# STM32H7P4 register map
File version: 2.0.0
CPU: CM7 r1p2, little endian, MPU, FPU, 4 interrupt priority bits
Registers are 32-bit, read-write, reset 0x0 unless marked. A register's access mark holds for its fields unless they carry their own. Offsets are from the block's base; [hi:lo] are bit positions; {n}, {i} and the like mark numbered series; 'fields as' and 'values as' point back to an identical list.

## EXTI — EXTI register block
Base 0x58000000
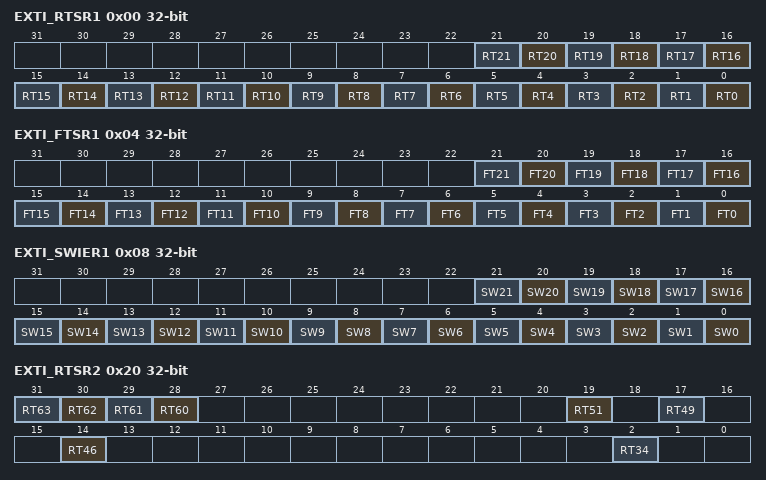
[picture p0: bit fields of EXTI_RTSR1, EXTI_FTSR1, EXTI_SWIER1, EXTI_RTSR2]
0x00 EXTI_RTSR1 — EXTI rising trigger selection register 1
  [all] fields
    0=Rising trigger disabled (for event and interrupt) for input line i; 1=Rising trigger enabled (for event and interrupt) for input line i
  [n] RT{n} (n=0..21) — Rising trigger event configuration bit of configurable event input i
0x04 EXTI_FTSR1 — EXTI falling trigger selection register 1
  [all] fields
    0=Falling trigger disabled (for event and interrupt) for input line i; 1=Falling trigger enabled (for event and interrupt) for input line i
  [n] FT{n} (n=0..21) — Falling trigger event configuration bit of configurable event input i
0x08 EXTI_SWIER1 — EXTI software interrupt event register 1
  [all] fields
    0=Writing 0 has no effect; 1=Writing a 1 to this bit triggers an event on line i. This bit is auto cleared by hardware.
  [n] SW{n} (n=0..21) — Software interrupt on event i
0x20 EXTI_RTSR2 — EXTI rising trigger selection register 2
  [n-32] RT{n} (n=60..63) — Rising trigger event configuration bit of configurable event input i
    values as the fields of EXTI_RTSR1
  [19] RT51 — Rising trigger event configuration bit of configurable event input 51less thansup>(1)less than/sup>
    0=Rising trigger disabled (for event and interrupt) for input line 51; 1=Rising trigger enabled (for event and interrupt) for input line 51
  [17] RT49 — Rising trigger event configuration bit of configurable event input 49less thansup>(1)less than/sup>
    0=Rising trigger disabled (for event and interrupt) for input line 49; 1=Rising trigger enabled (for event and interrupt) for input line 49
  [14] RT46 — Rising trigger event configuration bit of configurable event input 46less thansup>(1)less than/sup>
    0=Rising trigger disabled (for event and interrupt) for input line 46; 1=Rising trigger enabled (for event and interrupt) for input line 46
  [2] RT34 — Rising trigger event configuration bit of configurable event input 34less thansup>(1)less than/sup>
    0=Rising trigger disabled (for event and interrupt) for input line 34; 1=Rising trigger enabled (for event and interrupt) for input line 34
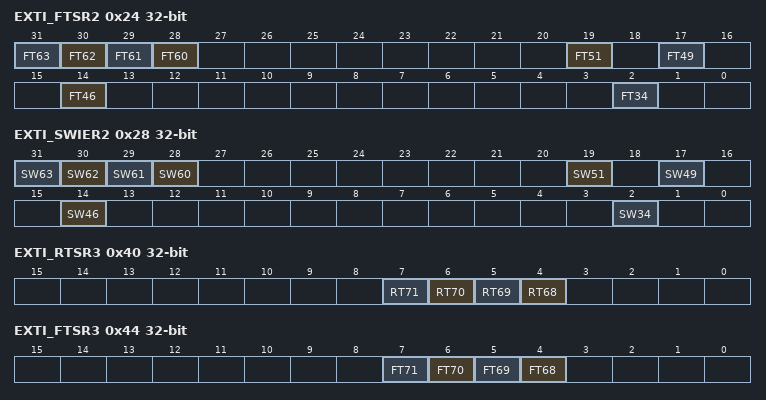
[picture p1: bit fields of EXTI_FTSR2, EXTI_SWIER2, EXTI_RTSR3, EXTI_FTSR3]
0x24 EXTI_FTSR2 — EXTI falling trigger selection register 2
  [n-32] FT{n} (n=60..63) — Falling trigger event configuration bit of configurable event input i
    values as the fields of EXTI_FTSR1
  [19] FT51 — Falling trigger event configuration bit of configurable event input 51less thansup>(1)less than/sup>
    0=Falling trigger disabled (for event and interrupt) for input line 51; 1=Falling trigger enabled (for event and interrupt) for input line 51
  [17] FT49 — Falling trigger event configuration bit of configurable event input 49less thansup>(1)less than/sup>
    0=Falling trigger disabled (for event and interrupt) for input line 49; 1=Falling trigger enabled (for event and interrupt) for input line 49
  [14] FT46 — Falling trigger event configuration bit of configurable event input 46less thansup>(1)less than/sup>
    0=Falling trigger disabled (for event and interrupt) for input line 46; 1=Falling trigger enabled (for event and interrupt) for input line 46
  [2] FT34 — Falling trigger event configuration bit of configurable event input 34less thansup>(1)less than/sup>
    0=Falling trigger disabled (for event and interrupt) for input line 34; 1=Falling trigger enabled (for event and interrupt) for input line 34
0x28 EXTI_SWIER2 — EXTI software interrupt event register 2
  [n-32] SW{n} (n=60..63) — Software interrupt on event i
    values as the fields of EXTI_SWIER1
  [19] SW51 — Software interrupt on event 51
    0=Writing 0 has no effect; 1=Writing a 1 to this bit triggers an event on line 51. This bit is auto cleared by hardware.
  [17] SW49 — Software interrupt on event 49
    0=Writing 0 has no effect; 1=Writing a 1 to this bit triggers an event on line 49. This bit is auto cleared by hardware.
  [14] SW46 — Software interrupt on event 46
    0=Writing 0 has no effect; 1=Writing a 1 to this bit triggers an event on line 46. This bit is auto cleared by hardware.
  [2] SW34 — Software interrupt on event 34
    0=Writing 0 has no effect; 1=Writing a 1 to this bit triggers an event on line 34. This bit is auto cleared by hardware.
0x40 EXTI_RTSR3 — EXTI rising trigger selection register 3
  [all] fields
    values as the fields of EXTI_RTSR1
  [n-64] RT{n} (n=68..71) — Rising trigger event configuration bit of configurable event input i
0x44 EXTI_FTSR3 — EXTI falling trigger selection register 3
  [all] fields
    values as the fields of EXTI_FTSR1
  [n-64] FT{n} (n=68..71) — Falling trigger event configuration bit of configurable event input i
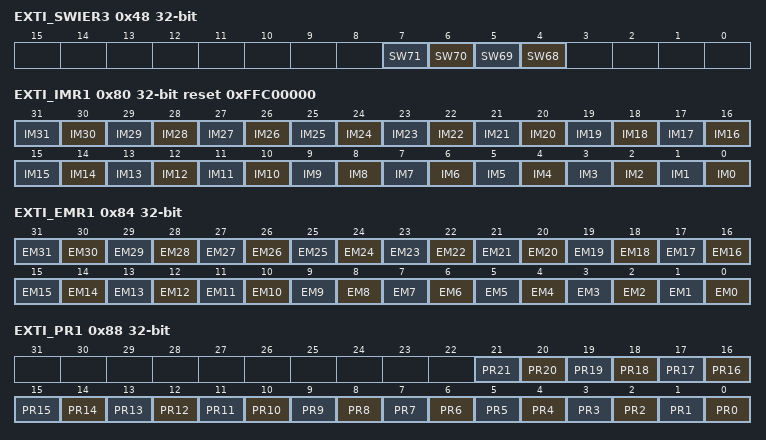
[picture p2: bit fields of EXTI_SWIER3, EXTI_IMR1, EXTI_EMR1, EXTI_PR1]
0x48 EXTI_SWIER3 — EXTI software interrupt event register 3
  [all] fields
    0=Writing 0 has no effect; 1=Writing a 1 to this bit triggers an event on line i. This bit is auto cleared by HW.
  [n-64] SW{n} (n=68..71) — Software interrupt on event i
0x80 EXTI_IMR1 reset 0xFFC00000 — EXTI interrupt mask register 1
  [all] fields
    0=Interrupt request from line x is masked; 1=Interrupt request from line x is unmasked
  [n] IM{n} (n=0..31) — CPU interrupt mask on event input i
0x84 EXTI_EMR1 — EXTI event mask register 1
  [all] fields
    0=Event request from line i is masked; 1=Event request from line i is unmasked
  [n] EM{n} (n=0..31) — CPU event mask on event input i
0x88 EXTI_PR1 — EXTI pending register 1
  [all] fields
    0=No trigger request occurred; 1=Selected trigger request occurred
  [n] PR{n} (n=0..21) — Configurable event input i pending
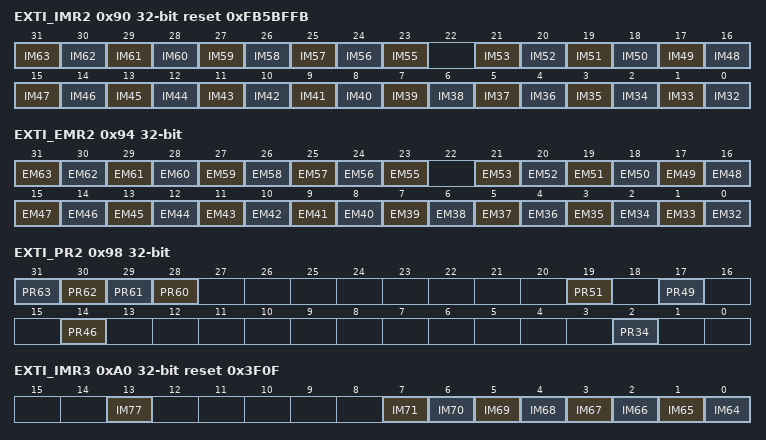
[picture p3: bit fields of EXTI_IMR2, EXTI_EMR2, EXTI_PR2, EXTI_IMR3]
0x90 EXTI_IMR2 reset 0xFB5BFFB — EXTI interrupt mask register 2
  [all] fields
    0=Interrupt request from line i is masked; 1=Interrupt request from line i is unmasked
  [n-32] IM{n} (n=55..63) — CPU interrupt mask on event input i
  [n-32] IM{n} (n=32..53) — CPU interrupt mask on event input i (i = 53 to 32)less thansup>(1)less than/sup>less thansup>(2)less than/sup>
0x94 EXTI_EMR2 — EXTI event mask register 2
  [all] fields
    values as the fields of EXTI_EMR1
  [n-32] EM{n} (n=55..63) — CPU event mask on event input i
  [n-32] EM{n} (n=32..53) — CPU event mask on event input i
0x98 EXTI_PR2 — EXTI pending register 2
  [n-32] PR{n} (n=60..63) — Configurable event input i pending
    values as the fields of EXTI_PR1
  [19] PR51 — Configurable event input 51 pending bit
    0=No trigger request occurred; 1=selected trigger request occurred
  [17] PR49 — Configurable event input 49 pending bit
    values as PR51
  [14] PR46 — Configurable event input 46 pending bit
    values as PR51
  [2] PR34 — Configurable event input 34 pending bit
    values as PR51
0xA0 EXTI_IMR3 reset 0x3F0F — EXTI interrupt mask register 3
  [13] IM77 — CPU interrupt mask on direct event input 77
    0=Interrupt request from line 77 is masked; 1=Interrupt request from line 77 is unmasked
  [n-64] IM{n} (n=64..71) — CPU interrupt mask on direct event input i (i = 71 to 64)less thansup>(1)less than/sup>
    values as the fields of EXTI_IMR2
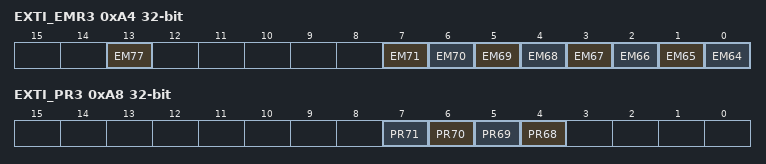
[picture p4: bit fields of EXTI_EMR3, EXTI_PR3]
0xA4 EXTI_EMR3 — EXTI event mask register 3
  [13] EM77 — CPU event mask on event input 77
    0=Event request from line 77 is masked; 1=Event request from line 77 is unmasked
  [n-64] EM{n} (n=64..71) — CPU event mask on event input i
    values as the fields of EXTI_EMR1
0xA8 EXTI_PR3 — EXTI pending register 3
  [all] fields
    values as EXTI_PR2.PR51
  [n-64] PR{n} (n=68..71) — Configurable event input i pending bit
